AUTOSAR XML (schema 4-2-2)
package /DBC_SysDesc_Can_Network/Pkg_Cluster
  can cluster Can_Network_0: baudrate=50000, protocol-name=CAN, protocol-version=chuyz@dfl.com.cn
    can physical channel Can_Network_0_Channel: comm-connectors=Conn_Can_Network_CANNODE_0_BMS
      frame HCU_12: id 0xC0928D0, to BMS, frame-length=8, can-addressing-mode=EXTENDED, can-frame-rx-behavior=ANY
        carries pdu HCU_12: packing-byte-order=little-endian, start-position=0, update-indication-bit-position=-1
        pdu HCU_12: length=8, transmission-mode-condition{data-filter={data-filter-type=ALWAYS, max=0, min=0, offset=0}, i-signal-in-i-pdu=HCU_VIN3Byte0}, transmission-mode-false-timing=cyclic-timing={time-offset=0.0, time-period=0.5}, transmission-mode-true-timing=cyclic-timing={time-offset=0.0, time-period=0.5}
          signal HCU_VIN3Byte0: start 0, 8 bit, little-endian, init-value=0, base-type=uint8, compu {raw=phys for phys 0}, update-indication-bit-position=-1, to BMS
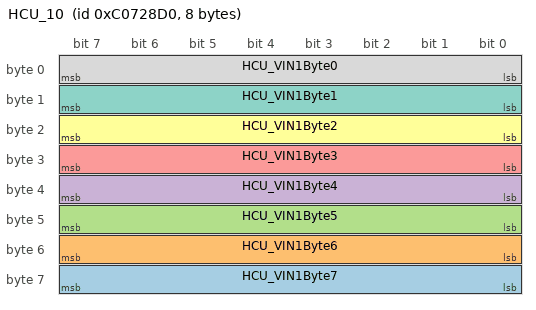
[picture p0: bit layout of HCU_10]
      frame HCU_10: id 0xC0728D0, to BMS, frame-length=8, can-addressing-mode=EXTENDED, can-frame-rx-behavior=ANY
        carries pdu HCU_10: packing-byte-order=little-endian, start-position=0, update-indication-bit-position=-1
        pdu HCU_10: length=8, transmission-mode-false-timing=cyclic-timing={time-offset=0.0, time-period=0.5}, transmission-mode-true-timing=cyclic-timing={time-offset=0.0, time-period=0.5}
          transmission-mode-conditions:
            {data-filter={data-filter-type=ALWAYS, max=0, min=0, offset=0}, i-signal-in-i-pdu=HCU_VIN1Byte7}
            {data-filter={data-filter-type=ALWAYS, max=0, min=0, offset=0}, i-signal-in-i-pdu=HCU_VIN1Byte6}
            {data-filter={data-filter-type=ALWAYS, max=0, min=0, offset=0}, i-signal-in-i-pdu=HCU_VIN1Byte5}
            {data-filter={data-filter-type=ALWAYS, max=0, min=0, offset=0}, i-signal-in-i-pdu=HCU_VIN1Byte4}
            {data-filter={data-filter-type=ALWAYS, max=0, min=0, offset=0}, i-signal-in-i-pdu=HCU_VIN1Byte3}
            {data-filter={data-filter-type=ALWAYS, max=0, min=0, offset=0}, i-signal-in-i-pdu=HCU_VIN1Byte2}
            {data-filter={data-filter-type=ALWAYS, max=0, min=0, offset=0}, i-signal-in-i-pdu=HCU_VIN1Byte1}
            {data-filter={data-filter-type=ALWAYS, max=0, min=0, offset=0}, i-signal-in-i-pdu=HCU_VIN1Byte0}
          signal HCU_VIN1Byte7: start 56, 8 bit, little-endian, init-value=0, base-type=uint8, compu {raw=phys for phys 0}, update-indication-bit-position=-1, to BMS
          signal HCU_VIN1Byte6: start 48, 8 bit, little-endian, init-value=0, base-type=uint8, compu {raw=phys for phys 0}, update-indication-bit-position=-1, to BMS
          signal HCU_VIN1Byte5: start 40, 8 bit, little-endian, init-value=0, base-type=uint8, compu {raw=phys for phys 0}, update-indication-bit-position=-1, to BMS
          signal HCU_VIN1Byte4: start 32, 8 bit, little-endian, init-value=0, base-type=uint8, compu {raw=phys for phys 0}, update-indication-bit-position=-1, to BMS
          signal HCU_VIN1Byte3: start 24, 8 bit, little-endian, init-value=0, base-type=uint8, compu {raw=phys for phys 0}, update-indication-bit-position=-1, to BMS
          signal HCU_VIN1Byte2: start 16, 8 bit, little-endian, init-value=0, base-type=uint8, compu {raw=phys for phys 0}, update-indication-bit-position=-1, to BMS
          signal HCU_VIN1Byte1: start 8, 8 bit, little-endian, init-value=0, base-type=uint8, compu {raw=phys for phys 0}, update-indication-bit-position=-1, to BMS
          signal HCU_VIN1Byte0: start 0, 8 bit, little-endian, init-value=0, base-type=uint8, compu {raw=phys for phys 0}, update-indication-bit-position=-1, to BMS
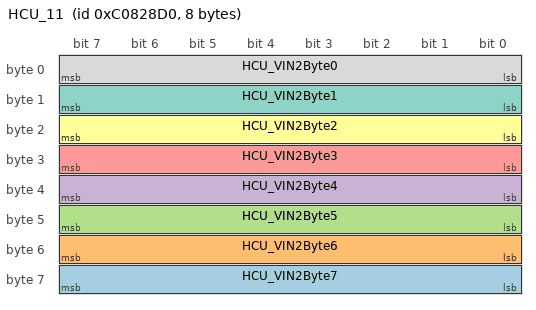
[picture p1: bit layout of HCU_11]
      frame HCU_11: id 0xC0828D0, to BMS, frame-length=8, can-addressing-mode=EXTENDED, can-frame-rx-behavior=ANY
        carries pdu HCU_11: packing-byte-order=little-endian, start-position=0, update-indication-bit-position=-1
        pdu HCU_11: length=8, transmission-mode-false-timing=cyclic-timing={time-offset=0.0, time-period=0.5}, transmission-mode-true-timing=cyclic-timing={time-offset=0.0, time-period=0.5}
          transmission-mode-conditions:
            {data-filter={data-filter-type=ALWAYS, max=0, min=0, offset=0}, i-signal-in-i-pdu=HCU_VIN2Byte7}
            {data-filter={data-filter-type=ALWAYS, max=0, min=0, offset=0}, i-signal-in-i-pdu=HCU_VIN2Byte6}
            {data-filter={data-filter-type=ALWAYS, max=0, min=0, offset=0}, i-signal-in-i-pdu=HCU_VIN2Byte5}
            {data-filter={data-filter-type=ALWAYS, max=0, min=0, offset=0}, i-signal-in-i-pdu=HCU_VIN2Byte4}
            {data-filter={data-filter-type=ALWAYS, max=0, min=0, offset=0}, i-signal-in-i-pdu=HCU_VIN2Byte3}
            {data-filter={data-filter-type=ALWAYS, max=0, min=0, offset=0}, i-signal-in-i-pdu=HCU_VIN2Byte2}
            {data-filter={data-filter-type=ALWAYS, max=0, min=0, offset=0}, i-signal-in-i-pdu=HCU_VIN2Byte1}
            {data-filter={data-filter-type=ALWAYS, max=0, min=0, offset=0}, i-signal-in-i-pdu=HCU_VIN2Byte0}
          signal HCU_VIN2Byte7: start 56, 8 bit, little-endian, init-value=0, base-type=uint8, compu {raw=phys for phys 0}, update-indication-bit-position=-1, to BMS
          signal HCU_VIN2Byte6: start 48, 8 bit, little-endian, init-value=0, base-type=uint8, compu {raw=phys for phys 0}, update-indication-bit-position=-1, to BMS
          signal HCU_VIN2Byte5: start 40, 8 bit, little-endian, init-value=0, base-type=uint8, compu {raw=phys for phys 0}, update-indication-bit-position=-1, to BMS
          signal HCU_VIN2Byte4: start 32, 8 bit, little-endian, init-value=0, base-type=uint8, compu {raw=phys for phys 0}, update-indication-bit-position=-1, to BMS
          signal HCU_VIN2Byte3: start 24, 8 bit, little-endian, init-value=0, base-type=uint8, compu {raw=phys for phys 0}, update-indication-bit-position=-1, to BMS
          signal HCU_VIN2Byte2: start 16, 8 bit, little-endian, init-value=0, base-type=uint8, compu {raw=phys for phys 0}, update-indication-bit-position=-1, to BMS
          signal HCU_VIN2Byte1: start 8, 8 bit, little-endian, init-value=0, base-type=uint8, compu {raw=phys for phys 0}, update-indication-bit-position=-1, to BMS
          signal HCU_VIN2Byte0: start 0, 8 bit, little-endian, init-value=0, base-type=uint8, compu {raw=phys for phys 0}, update-indication-bit-position=-1, to BMS
      frame HCU_2: id 0x18FF9131, to BMS, frame-length=8, can-addressing-mode=EXTENDED, can-frame-rx-behavior=ANY
        carries pdu HCU_2: packing-byte-order=little-endian, start-position=0, update-indication-bit-position=-1
        pdu HCU_2: length=8, transmission-mode-false-timing=cyclic-timing={time-offset=0.0, time-period=0.1}, transmission-mode-true-timing=cyclic-timing={time-offset=0.0, time-period=0.1}
          transmission-mode-conditions:
            {data-filter={data-filter-type=ALWAYS, max=0, min=0, offset=0}, i-signal-in-i-pdu=Transcendental_mode}
            {data-filter={data-filter-type=ALWAYS, max=0, min=0, offset=0}, i-signal-in-i-pdu=HCU_ChgWakeup}
            {data-filter={data-filter-type=ALWAYS, max=0, min=0, offset=0}, i-signal-in-i-pdu=HCU_WakeupPow}
            {data-filter={data-filter-type=ALWAYS, max=0, min=0, offset=0}, i-signal-in-i-pdu=TCU_fanUnlock}
            {data-filter={data-filter-type=ALWAYS, max=0, min=0, offset=0}, i-signal-in-i-pdu=TCU_EVUnlock}
            {data-filter={data-filter-type=ALWAYS, max=0, min=0, offset=0}, i-signal-in-i-pdu=CCVS2_PauseRES}
            {data-filter={data-filter-type=ALWAYS, max=0, min=0, offset=0}, i-signal-in-i-pdu=HCU_KeyPosition}
            {data-filter={data-filter-type=ALWAYS, max=0, min=0, offset=0}, i-signal-in-i-pdu=TCU_PTCUnlock}
            {data-filter={data-filter-type=ALWAYS, max=0, min=0, offset=0}, i-signal-in-i-pdu=TCU_ACUnlock}
            {data-filter={data-filter-type=ALWAYS, max=0, min=0, offset=0}, i-signal-in-i-pdu=HCU_ACCompressorWorkEnCmd}
            {data-filter={data-filter-type=ALWAYS, max=0, min=0, offset=0}, i-signal-in-i-pdu=HCU_PwrOffAllow}
            {data-filter={data-filter-type=ALWAYS, max=0, min=0, offset=0}, i-signal-in-i-pdu=HCU_DriveMode}
            {data-filter={data-filter-type=ALWAYS, max=0, min=0, offset=0}, i-signal-in-i-pdu=HCU_CruiseSts}
            {data-filter={data-filter-type=NEW-IS-WITHIN, max=0, min=0, offset=0}, i-signal-in-i-pdu=Fuel_range}
            {data-filter={data-filter-type=ALWAYS, max=0, min=0, offset=0}, i-signal-in-i-pdu=Pure_electric_range}
            {data-filter={data-filter-type=ALWAYS, max=0, min=0, offset=0}, i-signal-in-i-pdu=HCU_Cruise__Pause_sts}
            {data-filter={data-filter-type=ALWAYS, max=0, min=0, offset=0}, i-signal-in-i-pdu=HCU_ChrgSts}
            {data-filter={data-filter-type=ALWAYS, max=0, min=0, offset=0}, i-signal-in-i-pdu=BMS_charge_response}
            {data-filter={data-filter-type=ALWAYS, max=0, min=0, offset=0}, i-signal-in-i-pdu=MCU2_MotorTempExtreOver}
            {data-filter={data-filter-type=ALWAYS, max=0, min=0, offset=0}, i-signal-in-i-pdu=MCU1_MotorTempExtreOver}
            {data-filter={data-filter-type=ALWAYS, max=0, min=0, offset=0}, i-signal-in-i-pdu=HCU_CruiseSpd}
          signal Transcendental_mode: start 62, 2 bit, little-endian, init-value=0, base-type=uint8, compu {raw=phys for phys 0}, update-indication-bit-position=-1, to BMS
          signal HCU_ChgWakeup: start 60, 2 bit, little-endian, init-value=0, base-type=uint8, compu {raw=phys for phys 0}, update-indication-bit-position=-1, to BMS
          signal HCU_WakeupPow: start 58, 2 bit, little-endian, init-value=0, base-type=uint8, compu {raw=phys for phys 0}, update-indication-bit-position=-1, to BMS
          signal TCU_fanUnlock: start 56, 2 bit, little-endian, init-value=0, base-type=uint8, compu {raw=phys for phys 0, 0=OFF, 1=ΜÍËÙ·ÇÉÈ¿ªÆÔ, 2=SS_, 3=SS_}, update-indication-bit-position=-1, to BMS
          signal TCU_EVUnlock: start 55, 1 bit, little-endian, init-value=0, base-type=uint8, compu {raw=phys for phys 0, 0=ÎÞÐ§, 1=ÓÐÐ§}, update-indication-bit-position=-1, to BMS
          signal CCVS2_PauseRES: start 53, 2 bit, little-endian, init-value=0, base-type=uint8, compu {raw=phys for phys 0}, update-indication-bit-position=-1, to BMS
          signal HCU_KeyPosition: start 51, 2 bit, little-endian, init-value=0, base-type=uint8, compu {raw=phys for phys 0, 0=OFF, 1=ON, 2=START, 3=Ô¤ÁÔ}, update-indication-bit-position=-1, to BMS
          signal TCU_PTCUnlock: start 50, 1 bit, little-endian, init-value=0, base-type=uint8, compu {raw=phys for phys 0, 0=ÎÞÐ§, 1=ÓÐÐ§}, update-indication-bit-position=-1, to BMS
          signal TCU_ACUnlock: start 49, 1 bit, little-endian, init-value=0, base-type=uint8, compu {raw=phys for phys 0, 0=ÎÞÐ§, 1=ÓÐÐ§}, update-indication-bit-position=-1, to BMS
          signal HCU_ACCompressorWorkEnCmd: start 48, 1 bit, little-endian, init-value=0, base-type=uint8, compu {raw=phys for phys 0, 0=½ÛÓÃ, 1=Ê¹ÄÜ}, update-indication-bit-position=-1, to BMS
          signal HCU_PwrOffAllow: start 46, 2 bit, little-endian, init-value=0, base-type=uint8, compu {raw=phys for phys 0, 0=ºÖÂÔÅÐ¶Ï, 1=ÔÊÐÍÖ÷¸ºÉÏΜÇ, 2=¶ÏÖ÷¸ºÏÂΜÇ}, update-indication-bit-position=-1, to BMS
          signal HCU_DriveMode: start 42, 4 bit, little-endian, init-value=0, base-type=uint8, compu-method=CompuMethod_HCU_DriveMode, update-indication-bit-position=-1, to BMS
          signal HCU_CruiseSts: start 40, 2 bit, little-endian, init-value=0, base-type=uint8, compu {raw=phys for phys 0, 0=Ñ²º½¹Ø±Õ, 1=Ñ²º½¿ªÆÔ, 2=Ô¤ÁÔ; unit Km}, update-indication-bit-position=-1, to BMS
          signal Fuel_range: start 24, 16 bit, little-endian, init-value=0, base-type=uint16, compu {raw=phys for phys 0}, update-indication-bit-position=-1, to BMS
          signal Pure_electric_range: start 16, 8 bit, little-endian, init-value=0, base-type=uint8, compu {raw=phys for phys 0}, update-indication-bit-position=-1, to BMS
          signal HCU_Cruise__Pause_sts: start 14, 2 bit, little-endian, init-value=0, base-type=uint8, compu {raw=phys for phys 0, 0=Ñ²º½ÕÝ³£, 1=Ñ²º½ÔÝÍ£, 2=Ô¤ÁÔ}, update-indication-bit-position=-1, to BMS
          signal HCU_ChrgSts: start 12, 2 bit, little-endian, init-value=0, base-type=uint8, compu {raw=phys for phys 0, 0=RESERVED, 1=³ÄΜÇ¹Ý³ÌÖÐ, 2=³ÄΜÇ¹ÊÕÏ, 3=³ÄΜÇÍÊ³É}, update-indication-bit-position=-1, to BMS
          signal BMS_charge_response: start 10, 2 bit, little-endian, init-value=0, base-type=uint8, compu-method=CompuMethod_BMS_charge_response, update-indication-bit-position=-1, to BMS
          signal MCU2_MotorTempExtreOver: start 9, 1 bit, little-endian, init-value=0, base-type=uint8, compu {raw=phys for phys 0, 0=ÕÝ³£, 1=¹ÊÕÏ}, update-indication-bit-position=-1, to BMS
          signal MCU1_MotorTempExtreOver: start 8, 1 bit, little-endian, init-value=0, base-type=uint8, compu {raw=phys for phys 0, 0=ÕÝ³£, 1=¹ÊÕÏ}, update-indication-bit-position=-1, to BMS
          signal HCU_CruiseSpd: start 0, 8 bit, little-endian, init-value=0, base-type=uint8, compu {raw=phys for phys 0}, update-indication-bit-position=-1, to BMS
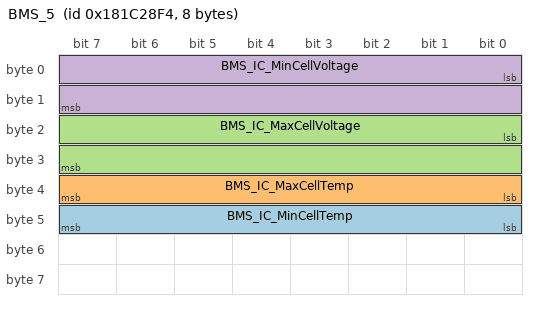
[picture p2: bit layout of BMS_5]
      frame BMS_5: id 0x181C28F4, from BMS, frame-length=8, can-addressing-mode=EXTENDED
        carries pdu BMS_5: packing-byte-order=little-endian, start-position=0, update-indication-bit-position=-1
        pdu BMS_5: length=8, transmission-mode-false-timing=cyclic-timing={time-offset=0.0, time-period=0.1}, transmission-mode-true-timing=cyclic-timing={time-offset=0.0, time-period=0.1}
          transmission-mode-conditions:
            {data-filter={data-filter-type=ALWAYS, max=50, min=50}, i-signal-in-i-pdu=BMS_IC_MinCellTemp}
            {data-filter={data-filter-type=ALWAYS, max=50, min=50}, i-signal-in-i-pdu=BMS_IC_MaxCellTemp}
            {data-filter={data-filter-type=NEW-IS-WITHIN, max=0, min=0, offset=0}, i-signal-in-i-pdu=BMS_IC_MaxCellVoltage}
            {data-filter={data-filter-type=NEW-IS-WITHIN, max=0, min=0, offset=0}, i-signal-in-i-pdu=BMS_IC_MinCellVoltage}
          signal BMS_IC_MinCellTemp: start 40, 8 bit, little-endian, init-value=0, base-type=uint8, compu {raw=phys+50 for phys 0}, update-indication-bit-position=-1
          signal BMS_IC_MaxCellTemp: start 32, 8 bit, little-endian, init-value=0, base-type=uint8, compu {raw=phys+50 for phys 0}, update-indication-bit-position=-1
          signal BMS_IC_MaxCellVoltage: start 16, 16 bit, little-endian, init-value=0, base-type=uint16, compu {raw=phys*100 for phys 0; unit V}, update-indication-bit-position=-1
          signal BMS_IC_MinCellVoltage: start 0, 16 bit, little-endian, init-value=0, base-type=uint16, compu {raw=phys*100 for phys 0; unit V}, update-indication-bit-position=-1
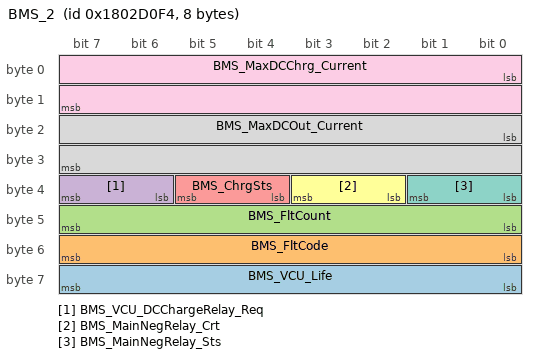
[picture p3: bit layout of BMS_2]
      frame BMS_2: id 0x1802D0F4, from BMS, frame-length=8, can-addressing-mode=EXTENDED
        carries pdu BMS_2: packing-byte-order=little-endian, start-position=0, update-indication-bit-position=-1
        pdu BMS_2: length=8, transmission-mode-false-timing=cyclic-timing={time-offset=0.0, time-period=0.1}, transmission-mode-true-timing=cyclic-timing={time-offset=0.0, time-period=0.1}
          transmission-mode-conditions:
            {data-filter={data-filter-type=ALWAYS, max=0, min=0, offset=0}, i-signal-in-i-pdu=BMS_VCU_Life}
            {data-filter={data-filter-type=ALWAYS, max=0, min=0, offset=0}, i-signal-in-i-pdu=BMS_FltCode}
            {data-filter={data-filter-type=ALWAYS, max=0, min=0, offset=0}, i-signal-in-i-pdu=BMS_FltCount}
            {data-filter={data-filter-type=ALWAYS, max=0, min=0, offset=0}, i-signal-in-i-pdu=BMS_VCU_DCChargeRelay_Req}
            {data-filter={data-filter-type=ALWAYS, max=0, min=0, offset=0}, i-signal-in-i-pdu=BMS_ChrgSts}
            {data-filter={data-filter-type=ALWAYS, max=0, min=0, offset=0}, i-signal-in-i-pdu=BMS_MainNegRelay_Crt}
            {data-filter={data-filter-type=ALWAYS, max=0, min=0, offset=0}, i-signal-in-i-pdu=BMS_MainNegRelay_Sts}
            {data-filter={data-filter-type=NEW-IS-WITHIN, max=32000, min=32000}, i-signal-in-i-pdu=BMS_MaxDCOut_Current}
            {data-filter={data-filter-type=NEW-IS-WITHIN, max=32000, min=32000}, i-signal-in-i-pdu=BMS_MaxDCChrg_Current}
          signal BMS_VCU_Life: start 56, 8 bit, little-endian, init-value=0, base-type=uint8, compu {raw=phys for phys 0; unit bit}, update-indication-bit-position=-1
          signal BMS_FltCode: start 48, 8 bit, little-endian, init-value=0, base-type=uint8, compu {raw=phys for phys 0}, update-indication-bit-position=-1
          signal BMS_FltCount: start 40, 8 bit, little-endian, init-value=0, base-type=uint8, compu {raw=phys for phys 0}, update-indication-bit-position=-1
          signal BMS_VCU_DCChargeRelay_Req: start 38, 2 bit, little-endian, init-value=0, base-type=uint8, compu-method=CompuMethod_BMS_VCU_DCChargeRelay_Req, update-indication-bit-position=-1
          signal BMS_ChrgSts: start 36, 2 bit, little-endian, init-value=0, base-type=uint8, compu {raw=phys for phys 0, 0=RESERVED, 1=³ÄΜÇ¹Ý³ÌÖÐ, 2=³ÄΜÇ¹ÊÕÏ, 3=³ÄΜÇÍÊ³É}, update-indication-bit-position=-1
          signal BMS_MainNegRelay_Crt: start 34, 2 bit, little-endian, init-value=0, base-type=uint8, compu-method=CompuMethod_BMS_MainNegRelay_Crt, update-indication-bit-position=-1
          signal BMS_MainNegRelay_Sts: start 32, 2 bit, little-endian, init-value=0, base-type=uint8, compu-method=CompuMethod_BMS_MainNegRelay_Sts, update-indication-bit-position=-1
          signal BMS_MaxDCOut_Current: start 16, 16 bit, little-endian, init-value=0, base-type=uint16, compu {raw=phys*10+32000 for phys 0}, update-indication-bit-position=-1
          signal BMS_MaxDCChrg_Current: start 0, 16 bit, little-endian, init-value=0, base-type=uint16, compu {raw=phys*10+32000 for phys 0}, update-indication-bit-position=-1
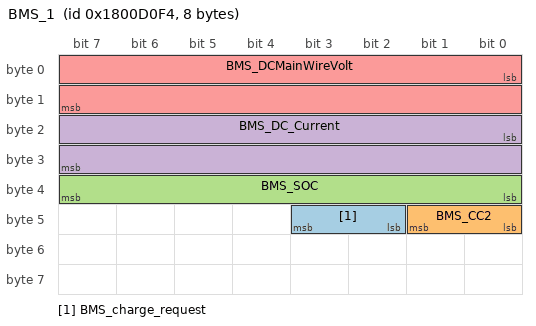
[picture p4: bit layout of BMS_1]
      frame BMS_1: id 0x1800D0F4, from BMS, frame-length=8, can-addressing-mode=EXTENDED
        carries pdu BMS_1: packing-byte-order=little-endian, start-position=0, update-indication-bit-position=-1
        pdu BMS_1: length=8, transmission-mode-false-timing=cyclic-timing={time-offset=0.0, time-period=0.1}, transmission-mode-true-timing=cyclic-timing={time-offset=0.0, time-period=0.1}
          transmission-mode-conditions:
            {data-filter={data-filter-type=ALWAYS, max=0, min=0, offset=0}, i-signal-in-i-pdu=BMS_charge_request}
            {data-filter={data-filter-type=ALWAYS, max=0, min=0, offset=0}, i-signal-in-i-pdu=BMS_CC2}
            {data-filter={data-filter-type=ALWAYS, max=0, min=0, offset=0}, i-signal-in-i-pdu=BMS_SOC}
            {data-filter={data-filter-type=NEW-IS-WITHIN, max=32000, min=32000}, i-signal-in-i-pdu=BMS_DC_Current}
            {data-filter={data-filter-type=NEW-IS-WITHIN, max=0, min=0, offset=0}, i-signal-in-i-pdu=BMS_DCMainWireVolt}
          signal BMS_charge_request: start 42, 2 bit, little-endian, init-value=0, base-type=uint8, compu {raw=phys for phys 0, 0=NO_REQUEST, 1=REQUEST, 2=ÎÞÐ§, 3=RESERVED}, update-indication-bit-position=-1
          signal BMS_CC2: start 40, 2 bit, little-endian, init-value=0, base-type=uint8, compu-method=CompuMethod_BMS_CC2, update-indication-bit-position=-1
          signal BMS_SOC: start 32, 8 bit, little-endian, init-value=0, base-type=uint8, compu {raw=phys*250 for phys 0}, update-indication-bit-position=-1
          signal BMS_DC_Current: start 16, 16 bit, little-endian, init-value=0, base-type=uint16, compu {raw=phys*10+32000 for phys 0}, update-indication-bit-position=-1
          signal BMS_DCMainWireVolt: start 0, 16 bit, little-endian, init-value=0, base-type=uint16, compu {raw=phys*10 for phys 0}, update-indication-bit-position=-1
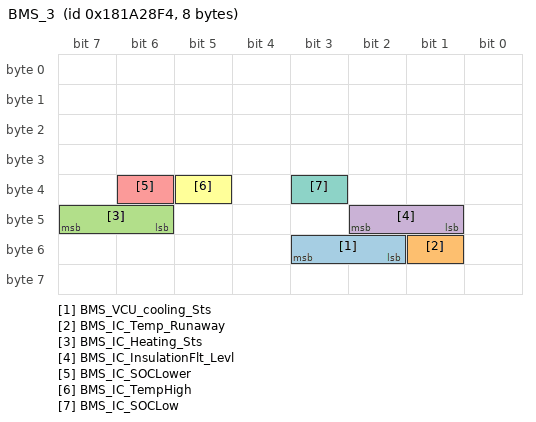
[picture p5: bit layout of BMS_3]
      frame BMS_3: id 0x181A28F4, from BMS, frame-length=8, can-addressing-mode=EXTENDED
        carries pdu BMS_3: packing-byte-order=little-endian, start-position=0, update-indication-bit-position=-1
        pdu BMS_3: length=8, transmission-mode-false-timing=cyclic-timing={time-offset=0.0, time-period=0.1}, transmission-mode-true-timing=cyclic-timing={time-offset=0.0, time-period=0.1}
          transmission-mode-conditions:
            {data-filter={data-filter-type=ALWAYS, max=0, min=0, offset=0}, i-signal-in-i-pdu=BMS_VCU_cooling_Sts}
            {data-filter={data-filter-type=ALWAYS, max=0, min=0, offset=0}, i-signal-in-i-pdu=BMS_IC_Temp_Runaway}
            {data-filter={data-filter-type=ALWAYS, max=0, min=0, offset=0}, i-signal-in-i-pdu=BMS_IC_Heating_Sts}
            {data-filter={data-filter-type=ALWAYS, max=0, min=0, offset=0}, i-signal-in-i-pdu=BMS_IC_InsulationFlt_Levl}
            {data-filter={data-filter-type=ALWAYS, max=0, min=0, offset=0}, i-signal-in-i-pdu=BMS_IC_SOCLower}
            {data-filter={data-filter-type=ALWAYS, max=0, min=0, offset=0}, i-signal-in-i-pdu=BMS_IC_TempHigh}
            {data-filter={data-filter-type=ALWAYS, max=0, min=0, offset=0}, i-signal-in-i-pdu=BMS_IC_SOCLow}
          signal BMS_VCU_cooling_Sts: start 50, 2 bit, little-endian, init-value=0, base-type=uint8, compu-method=CompuMethod_BMS_VCU_cooling_Sts, update-indication-bit-position=-1
          signal BMS_IC_Temp_Runaway: start 49, 1 bit, little-endian, init-value=0, base-type=uint8, compu {raw=phys for phys 0, 0=OFF, 1=ACTIVE; unit bit}, update-indication-bit-position=-1
          signal BMS_IC_Heating_Sts: start 46, 2 bit, little-endian, init-value=0, base-type=uint8, compu-method=CompuMethod_BMS_IC_Heating_Sts, update-indication-bit-position=-1
          signal BMS_IC_InsulationFlt_Levl: start 41, 2 bit, little-endian, init-value=0, base-type=uint8, compu {raw=phys for phys 0, 0=ÎÞ¹ÊÕÏ, 1=ÑÏÖØ¹ÊÕÏ, 2=×ÎÑÏÖØ¹ÊÕÏ; unit bit}, update-indication-bit-position=-1
          signal BMS_IC_SOCLower: start 38, 1 bit, little-endian, init-value=0, base-type=uint8, compu {raw=phys for phys 0, 0=OFF, 1=ACTIVE; unit bit}, update-indication-bit-position=-1
          signal BMS_IC_TempHigh: start 37, 1 bit, little-endian, init-value=0, base-type=uint8, compu {raw=phys for phys 0, 0=OFF, 1=ACTIVE; unit bit}, update-indication-bit-position=-1
          signal BMS_IC_SOCLow: start 35, 1 bit, little-endian, init-value=0, base-type=uint8, compu {raw=phys for phys 0, 0=OFF, 1=ACTIVE; unit bit}, update-indication-bit-position=-1
      frame BMS_12: id 0x18FED4F4, from BMS, frame-length=8, can-addressing-mode=EXTENDED
        carries pdu BMS_12: packing-byte-order=little-endian, start-position=0, update-indication-bit-position=-1
        pdu BMS_12: length=8, transmission-mode-condition{data-filter={data-filter-type=ALWAYS, max=0, min=0, offset=0}, i-signal-in-i-pdu=BMS_VCU_Heating_Req}, transmission-mode-false-timing=cyclic-timing={time-offset=0.0, time-period=0.1}, transmission-mode-true-timing=cyclic-timing={time-offset=0.0, time-period=0.1}
          signal BMS_VCU_Heating_Req: start 20, 2 bit, little-endian, init-value=0, base-type=uint8, compu-method=CompuMethod_BMS_VCU_Heating_Req, update-indication-bit-position=-1
package /DBC_SysDesc_Can_Network/Pkg_Ecu
  ecu instance BMS: com-configuration-gw-time-base=0.005, com-configuration-rx-time-base=0.01, com-configuration-tx-time-base=0.01, sleep-mode-supported=false, wake-up-over-bus-supported=false
    can communication controller Can_Network_CANNODE_0: can-controller-attributes=can-controller-configuration={prop-seg=0, sync-jump-width=0, time-seg-1=10, time-seg-2=0}
    can communication connector Conn_Can_Network_CANNODE_0_BMS: comm-controller=Can_Network_CANNODE_0
  module config EcuM
    EcuMConfiguration_0 (EcuMConfiguration)
      EcuMCommonConfiguration_0 (EcuMCommonConfiguration)
        EcuMDefaultShutdownTarget_0 (EcuMDefaultShutdownTarget): EcuMDefaultState=EcuMStateOff
        7 x EcuMWakeupSource, all with EcuMValidationTimeout=0.0:
          ECUM_WKSOURCE_POWER
          ECUM_WKSOURCE_RESET
          ECUM_WKSOURCE_INTERNAL_RESET
          ECUM_WKSOURCE_INTERNAL_WDG
          ECUM_WKSOURCE_EXTERNAL_WDG
          ECUM_WKSOURCE_CANMSG
          ECUM_WKSOURCE_KL15
        EcuMDriverInitListOne
          7 x EcuMDriverInitItem:
            Det: EcuMModuleParameter=NULL_PTR, EcuMModuleService=Init
            Dem_PreInit: EcuMModuleParameter=NULL_PTR, EcuMModuleService=PreInit
            Mcu: EcuMModuleParameter=POSTBUILD_PTR, EcuMModuleService=Init
            McuFunc: EcuMModuleParameter=VOID, EcuMModuleService=InitializeClock
            Gpt: EcuMModuleParameter=POSTBUILD_PTR, EcuMModuleService=Init
            Port: EcuMModuleParameter=POSTBUILD_PTR, EcuMModuleService=Init
            Pwm: EcuMModuleParameter=POSTBUILD_PTR, EcuMModuleService=Init
      EcuMFlexConfiguration_0 (EcuMFlexConfiguration)
        EcuMFlexUserConfig_0 (EcuMFlexUserConfig)
        EcuMResetMode_0 (EcuMResetMode)
        EcuMShutdownCause_0 (EcuMShutdownCause)
    EcuMGeneral_0 (EcuMGeneral): EcuMRbConfigCCASInit=0, EcuMRbSlaveCoreEarlierStart=0, EcuMRbStartupDuration=0
    EcuMFlexGeneral
package /DBC_SysDesc_Can_Network/Pkg_CompuMethod
  compu method CompuMethod_HCU_DriveMode: raw=phys for phys 0, 0=ÎÞÐ§, 1=´¿ΜÇÄ£Ê½, 2=»Ì¶¯Ä£Ê½, 3=È¼ÓÍÄ£Ê½; unit Km
  compu method CompuMethod_BMS_VCU_cooling_Sts: raw=phys for phys 0, 0=ºÖÂÔÅÐ¶Ï, 1=ΜÇ³Ø°ÜÀÄÈ´¹ÊÕÏ, 2=ΜÇ³Ø°ÜÀÄÈ´ÖÐ, 3=ΜÇ³Ø°Ü´¿ÀÄÈ´Ä£Ê½; unit bit
  compu method CompuMethod_BMS_MainNegRelay_Crt: raw=phys for phys 0, 0=ºÖÂÔÅÐ¶Ï£¨Î´ÇËÇÓ£©, 1=ÇËÇÓ¶Ï¿ªÖ÷¸º½Ó´¥Æ÷, 2=RESERVED, 3=RESERVED
  compu method CompuMethod_BMS_VCU_DCChargeRelay_Req: raw=phys for phys 0, 0=ÎÞÐ§, 1=ÇËÇÓÎÜºÏ¿Ì³Ä½Ó´¥Æ÷, 2=ÇËÇÓ¶Ï¿ª¿Ì³Ä½Ó´¥Æ÷_, 3=RESERVED; unit bit
  compu method CompuMethod_BMS_charge_response: raw=phys for phys 0, 0=ALLOWTHECHARGING, 1=NOTALLOWTHECHARGING, 2=RESERVDE, 3=ÎÞÐ§
  compu method CompuMethod_BMS_CC2: raw=phys for phys 0, 0=³ÄΜÇÇ¹Î´²ÅÈË, 1=³ÄΜÇÁ¬½Ó, 2=RESERVED, 3=RESERVED
  compu method CompuMethod_BMS_VCU_Heating_Req: raw=phys for phys 0, 0=ºÖÂÔÅÐ¶Ï, 1=ÇËÇÓ¿ªÆÔΜÇ³Ø¼ÓÈÈ, 2=ÇËÇÓ¹Ø±ÕΜÇ³Ø¼ÓÈÈ, 3=RESERVED; unit bit
  compu method CompuMethod_BMS_MainNegRelay_Sts: raw=phys for phys 0, 0=RESERVED, 1=Ö÷¸º½Ó´¥Æ÷ÎÜºÏ, 2=Ö÷¸º½Ó´¥Æ÷Î´ÎÜºÏ£»_, 3=Ö÷¸º½Ó´¥Æ÷¹ÊÕÏ
  compu method CompuMethod_BMS_IC_Heating_Sts: raw=phys for phys 0, 0=ÎÞ¹ÊÕÏ, 1=ΜÇ³Ø°Ü¼ÓÈÈ¹ÊÕÏ, 2=ΜÇ³Ø°Ü¼ÓÈÈÖÐ, 3=ΜÇ³Ø°Ü´¿¼ÓÈÈÄ£Ê½; unit bit
package /DBC_SysDesc_Can_Network/Pkg_Units
  4 x unit:
    Km
    bit
    NOUNIT
    V
